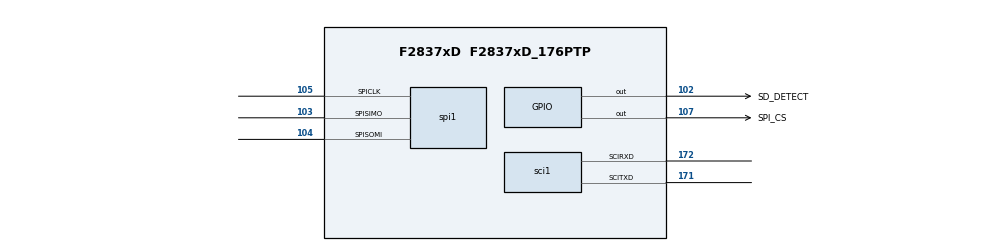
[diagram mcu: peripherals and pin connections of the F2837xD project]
/**
 * @cliArgs --device "F2837xD" --package "F2837xD_176PTP" --part "F2837xD_176PTP" --product "C2000WARE@3.00.00.00"
 * @versions {"data":"2021010520","timestamp":"2021010520","tool":"1.7.0+1746","templates":null}
 */

/**
 * Import the modules used in this configuration.
 */
const gpio  = scripting.addModule("/driverlib/gpio.js", {}, false);
const gpio1 = gpio.addInstance();
const gpio2 = gpio.addInstance();
const sci   = scripting.addModule("/driverlib/sci.js", {}, false);
const sci1  = sci.addInstance();
const spi   = scripting.addModule("/driverlib/spi.js", {}, false);
const spi1  = spi.addInstance();

/**
 * Write custom configuration values to the imported modules.
 */
gpio1.$name           = "SD_DETECT";
gpio1.masterCore      = "GPIO_CORE_CPU2";
gpio1.gpioPin.$assign = "102";

gpio2.$name           = "SPI_CS";
gpio2.masterCore      = "GPIO_CORE_CPU2";
gpio2.direction       = "GPIO_DIR_MODE_OUT";
gpio2.gpioPin.$assign = "107";

sci1.$name                 = "mySCI0";
sci1.useFifo               = false;
sci1.useInterrupts         = false;
sci1.sci.$assign           = "SCIC";
sci1.sci.scirxdPin.$assign = "172";
sci1.sci.scitxdPin.$assign = "171";

spi1.$name                  = "mySPI1";
spi1.mode                   = "SPI_MODE_MASTER";
spi1.dataWidth              = "8";
spi1.transferProtocol       = "SPI_PROT_POL1PHA0";
spi1.useInterrupts          = false;
spi1.useFifo                = false;
spi1.emulationMode          = "SPI_EMULATION_FREE_RUN";
spi1.bitRate                = 400000;
spi1.spi.$assign            = "SPIA";
spi1.spi.spisimoPin.$assign = "103";
spi1.spi.spisomiPin.$assign = "104";
spi1.spi.spiclkPin.$assign  = "105";

/**
 * Pinmux solution for unlocked pins/peripherals. This ensures that minor changes to the automatic solver in a future
 * version of the tool will not impact the pinmux you originally saw.  These lines can be completely deleted in order to
 * re-solve from scratch.
 */
spi1.spi.spistePin.$suggestSolution = "12";
